# RK3399-AP register map
File version: 1
CPU: CA7 r0p1, little endian, MPU, FPU, I-cache, D-cache, VTOR, 4 interrupt priority bits, 32 interrupts
Registers are 32-bit, read-write, reset 0x0 unless marked. A register's access mark holds for its fields unless they carry their own. Offsets are from the block's base; [hi:lo] are bit positions; {n}, {i} and the like mark numbered series; 'fields as' and 'values as' point back to an identical list.

## CCI500
Base 0xFFB00000
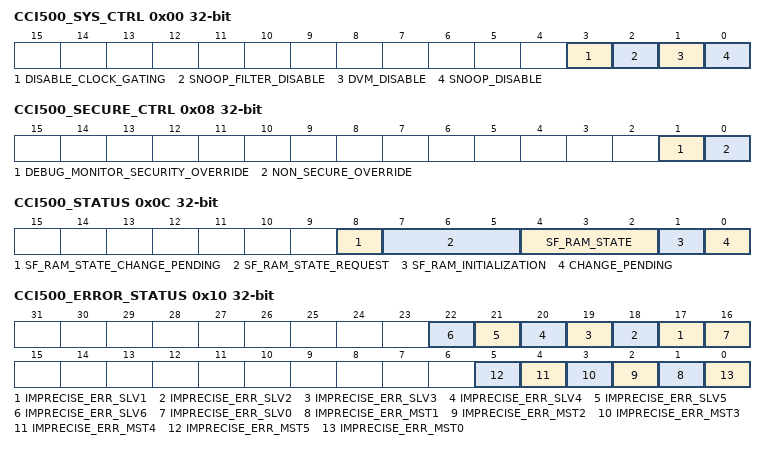
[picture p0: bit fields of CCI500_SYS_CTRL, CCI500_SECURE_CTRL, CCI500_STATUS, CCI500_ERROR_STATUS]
0x00 CCI500_SYS_CTRL — Control Override Register
  [3] DISABLE_CLOCK_GATING — Disable regional clock gating 0: Regional clock gating operates in the CCI-500 1: Disables regional clock gating in the CCI-500
  [2] SNOOP_FILTER_DISABLE — Disable the snoop filter 0: Snoop filter operation is defined by the power state input, PSTATE. 1: Disable snoop filter operation
  [1] DVM_DISABLE — DVM message disable 0: Send speculative fetches according to the Speculation Control Register 1: Disable speculative fetches from all master interfaces
  [0] SNOOP_DISABLE — snoop_disable control 0: Snoop masters according to the Snoop Control Registers 1: Disable all snoops, but not DVM messages
0x08 CCI500_SECURE_CTRL — Secure Access Register
  [1] DEBUG_MONITOR_SECURITY_OVERRIDE — 0: Enable Non-secure access to the PMU and Interface Monitor Registers. 1: Disable Non-secure access to the PMU and Interface Monitor Registers, unless overridden by bit[0]
  [0] NON_SECURE_OVERRIDE — Non-secure register access override 0: Disable Non-secure access to CCI-400 registers 1: Enable Non-secure access to CCI-400 registers
0x0C CCI500_STATUS — Status Register
  [8] SF_RAM_STATE_CHANGE_PENDING — Snoop filter RAM power state change pending. This bit reads back the PREQ input. 0b0: No change pending, any previous requests have been accepted or denied. 0b1: State change is pending and might be accepted or denied
  [7:5] SF_RAM_STATE_REQUEST — This is the last requested power state of the snoop filter RAMs Encoding as SF_RAM_state.
  [4:2] SF_RAM_STATE — The snoop filter RAM power states are 0b000: Off. 0b001: Static snoop filter RAM retention. 0b010: Reserved. 0b011: Dynamic snoop filter RAM retention. 0b100: On. 0b101-0b111 Reserved
  [1] SF_RAM_INITIALIZATION — Indicates when the snoop filter RAM is initialized. Shareable requests are not serviced during this period. 0: Snoop filter RAM initialization is complete. 1: Snoop filter RAM initialization is in progress.
  [0] CHANGE_PENDING — Indicates whether any changes to the Snoop Control Registers or the Control Override Register are pending in the CCI-500: 0: No change pending 1: Change pending
0x10 CCI500_ERROR_STATUS — Imprecise Error Register
  [n+16] IMPRECISE_ERR_SLV{n} (n=1..6) — Imprecise error indicator for slave interface {n} 0b0: No error from the time this bit was last reset. 0b1: An error response has been received, but not signaled precisely.
  [16] IMPRECISE_ERR_SLV0 — Imprecise error indicator for slave interface 0. 0b0: No error from the time this bit was last reset. 0b1: An error response has been received, but not signaled precisely.
  [n] IMPRECISE_ERR_MST{n} (n=1..5) — Imprecise error indicator for master interface {n} 0: No error from the time this bit was last reset. 1: An error response has been received, but not signalled precisely.
  [0] IMPRECISE_ERR_MST0 — Imprecise error indicator for master interface 0: 0: No error from the time this bit was last reset. 1: An error response has been received, but not signalled precisely.
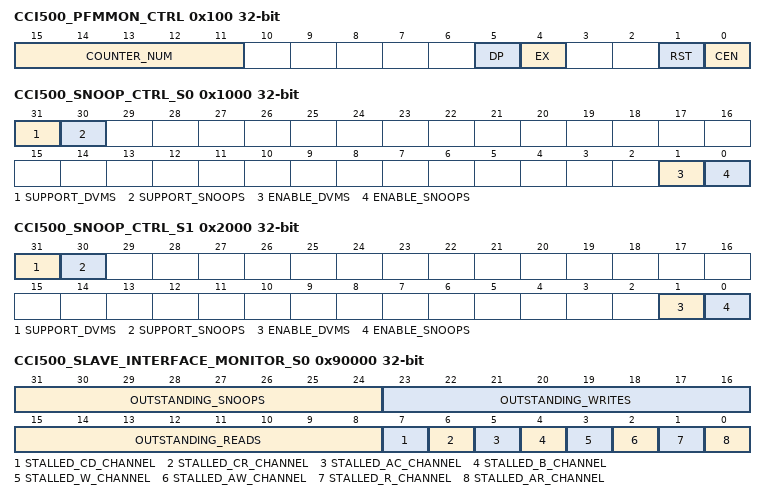
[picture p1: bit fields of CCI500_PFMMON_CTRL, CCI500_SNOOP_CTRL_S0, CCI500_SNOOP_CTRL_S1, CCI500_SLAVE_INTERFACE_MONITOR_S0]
0x100 CCI500_PFMMON_CTRL — Performance Monitor Control Register (PMCR)
  [15:11] COUNTER_NUM — Specifies the number of counters implemented.
  [5] DP — Disables cycle counter, CCNT, if non-invasive debug is prohibited: 0b0 Count is not disabled when NIDEN input is LOW. 0b1 Count is disabled when NIDEN input is LOW.
  [4] EX — Enable export of the events to the event bus, EVNTBUS, for an external monitoring block to trace events: 0b0 Do not export EVNTBUS. 0b1 Export EVNTBUS.
  [1] RST — Performance counter reset: 0b0 No action. 0b1 Reset all performance counters to zero, not including CCNT.
  [0] CEN — Enable bit: 0b0 Disable all counters, including CCNT. 0b1 Enable all counters, including CCNT.
0x104 CCI500_INTERFACE_MONITOR_CTRL — Snoop Control Register for slave interface x
  [0] ENABLE_INTERFACE_MONITORS — 0b0 Interface Monitor counters and flags are set to 0. 0b1 Enable all Interface Monitors.
0x1000 CCI500_SNOOP_CTRL_S0
  [31] SUPPORT_DVMS — Slave interface supports DVM messages. This is overridden to 0x0 if you set the Control Override Register bit[1]
  [30] SUPPORT_SNOOPS — Slave interface supports snoop requests. This is overridden to 0x0 if you set the Control Override Register bit[0]
  [1] ENABLE_DVMS — Enable issuing of DVM message requests from this slave interface. RAZ/WI for interfaces not supporting DVM messages: 0b0: Disable DVM message requests. 0b1: Enable DVM message requests.
  [0] ENABLE_SNOOPS — Enable issuing of snoop requests from this slave interface. RAZ/WI for interfaces not supporting snoops: 0b0: Disable snoop requests. 0b1: Enable snoop requests.
0x1004 CCI500_SHAREABLE_OVERRIDE_S0 — Shareable Override Register
  [1:0] DOMAIN_OVERRIDE — Shareable override for slave interface: 0b00-0b01: Do not override AxDOMAIN inputs. 0b10: Override AxDOMAIN inputs to 0b00, meaning that all transactions are treated as non-shareable: ReadOnce becomes ReadNoSnoop. WriteUnique and WriteLineUnique become WriteNoSnoop. CleanShared, CleanInvalid, and MakeInvalid transactions do not generate snoops. 0b11 Override AxDOMAIN inputs to 0b01, meaning that all Normal transactions are treated as shareable: ReadNoSnoop becomes ReadOnce. WriteNoSnoop becomes WriteUnique. CleanShared, CleanInvalid, and MakeInvalid transactions generate snoops
0x1100 CCI500_RD_CHAN_QOS_OVERRIDE_S0 — Read Channel QoS Value Override Register for slave interface x
  [3:0] ARQOS_OVERRIDE — ARQOS value override for the slave interface
0x1104 CCI500_WR_CHAN_QOS_OVERRIDE_S0 — Write Channel QoS Value Override slave interface x
  [3:0] AWQOS_OVERRIDE — AWQOS value override for the slave interface
0x1110 CCI500_MAX_OT_S0 — Maximum Outstanding Transactions Registers
  [0] MAX_OT — The maximum number of OTs for the interface. This is a combined issuing limit. It represents the maximum number of transactions that the upstream master can issue when the AR and AW channels are considered as one issuing source.
0x2000 CCI500_SNOOP_CTRL_S1
  fields as CCI500_SNOOP_CTRL_S0
0x2004 CCI500_SHAREABLE_OVERRIDE_S1 — Shareable Override Register
  fields as CCI500_SHAREABLE_OVERRIDE_S0
0x2100 CCI500_RD_CHAN_QOS_OVERRIDE_S1 — Read Channel QoS Value Override Register for slave interface x
  [3:0] ARQOS_OVERRIDE — ARQOS value override for the slave interface
0x2104 CCI500_WR_CHAN_QOS_OVERRIDE_S1 — Write Channel QoS Value Override slave interface x
  [3:0] AWQOS_OVERRIDE — AWQOS value override for the slave interface
0x2110 CCI500_MAX_OT_S1 — Maximum Outstanding Transactions Registers
  fields as CCI500_MAX_OT_S0
0x90000 CCI500_SLAVE_INTERFACE_MONITOR_S0 — Slave Interface Monitor Registers
  [31:24] OUTSTANDING_SNOOPS — Number of outstanding snoop requests or DVM messages. From request handshake to response or snoop data for a hit.
  [23:16] OUTSTANDING_WRITES — Number of outstanding write transactions. From request handshake to response for ACE Lite interfaces or WACK for ACE interfaces.
  [15:8] OUTSTANDING_READS — Number of outstanding read transactions. From request handshake to response or RACK for ACE interfaces.
  [7] STALLED_CD_CHANNEL — A transfer is stalled on the CD channel. CDVALID is HIGH. CDREADY is LOW. ACE slave only.
  [6] STALLED_CR_CHANNEL — A transfer is stalled on the CR channel. CRVALID is HIGH. CRREADY is LOW.
  [5] STALLED_AC_CHANNEL — A transfer is stalled on the AC channel. ACVALID is HIGH. ACREADY is LOW.
  [4] STALLED_B_CHANNEL — A transfer is stalled on the B channel. BVALID is HIGH BREADY is LOW.
  [3] STALLED_W_CHANNEL — A transfer is stalled on the W channel. WVALID is HIGH. WREADY is LOW.
  [2] STALLED_AW_CHANNEL — A transfer is stalled on the AW channel. AWVALID is HIGH. AWREADY is LOW.
  [1] STALLED_R_CHANNEL — A transfer is stalled on the R channel. RVALID is HIGH. RREADY is LOW.
  [0] STALLED_AR_CHANNEL — A transfer is stalled on the AR channel.ARVALID is HIGH. ARREADY is LOW.
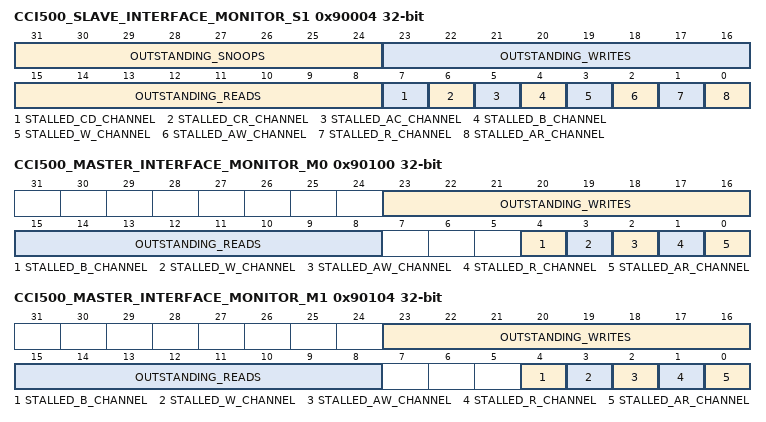
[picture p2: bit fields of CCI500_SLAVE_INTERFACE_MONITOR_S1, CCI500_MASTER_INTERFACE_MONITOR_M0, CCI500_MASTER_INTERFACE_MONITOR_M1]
0x90004 CCI500_SLAVE_INTERFACE_MONITOR_S1 — Slave Interface Monitor Registers
  fields as CCI500_SLAVE_INTERFACE_MONITOR_S0
0x90100 CCI500_MASTER_INTERFACE_MONITOR_M0 — Master Interface Monitor Registers
  [23:16] OUTSTANDING_WRITES — Number of outstanding write transactions. From request handshake to response.
  [15:8] OUTSTANDING_READS — Number of outstanding read transactions. From request handshake to response.
  [4] STALLED_B_CHANNEL — A transfer is stalled on the B channel. BVALID is HIGH BREADY is LOW.
  [3] STALLED_W_CHANNEL — A transfer is stalled on the W channel. WVALID is HIGH. WREADY is LOW.
  [2] STALLED_AW_CHANNEL — A transfer is stalled on the AW channel. AWVALID is HIGH. AWREADY is LOW.
  [1] STALLED_R_CHANNEL — A transfer is stalled on the R channel. RVALID is HIGH. RREADY is LOW.
  [0] STALLED_AR_CHANNEL — A transfer is stalled on the AR channel.ARVALID is HIGH. ARREADY is LOW
0x90104 CCI500_MASTER_INTERFACE_MONITOR_M1 — Master Interface Monitor Registers
  [23:16] OUTSTANDING_WRITES — Number of outstanding write transactions. From request handshake to response.
  [15:8] OUTSTANDING_READS — Number of outstanding read transactions. From request handshake to response.
  [4] STALLED_B_CHANNEL — A transfer is stalled on the B channel. BVALID is HIGH BREADY is LOW.
  [3] STALLED_W_CHANNEL — A transfer is stalled on the W channel. WVALID is HIGH. WREADY is LOW.
  [2] STALLED_AW_CHANNEL — A transfer is stalled on the AW channel. AWVALID is HIGH. AWREADY is LOW.
  [1] STALLED_R_CHANNEL — A transfer is stalled on the R channel. RVALID is HIGH. RREADY is LOW.
  [0] STALLED_AR_CHANNEL — A transfer is stalled on the AR channel.ARVALID is HIGH. ARREADY is LOW NFO ROL OBS
